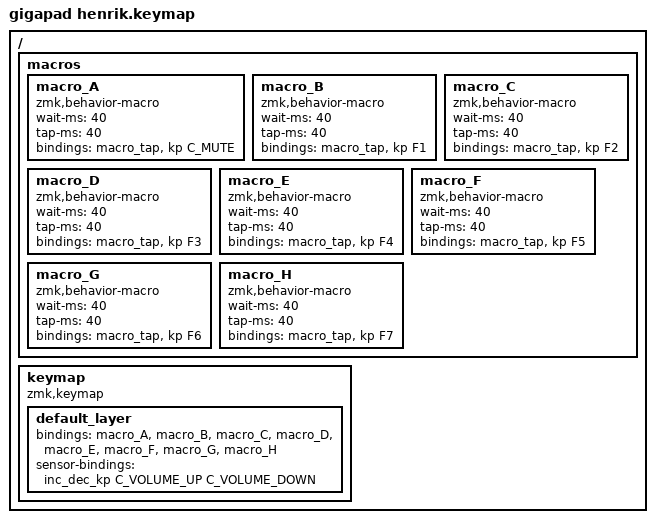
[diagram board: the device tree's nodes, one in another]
#include <behaviors.dtsi>
#include <dt-bindings/zmk/keys.h>
#include <dt-bindings/zmk/bt.h>
#include <dt-bindings/zmk/outputs.h>

/ {
    macros {
        macro_A: macro_A {
            compatible = "zmk,behavior-macro";
            #binding-cells = <0>;
            wait-ms = <40>;
            tap-ms = <40>;
            bindings = 
                <&macro_tap &kp C_MUTE>;
        };
        macro_B: macro_B {
            compatible = "zmk,behavior-macro";
            #binding-cells = <0>;
            wait-ms = <40>;
            tap-ms = <40>;
            bindings = 
                <&macro_tap &kp F1>;
        };
        macro_C: macro_C {
            compatible = "zmk,behavior-macro";
            #binding-cells = <0>;
            wait-ms = <40>;
            tap-ms = <40>;
            bindings = 
                <&macro_tap &kp F2>;
        };
        macro_D: macro_D {
            compatible = "zmk,behavior-macro";
            #binding-cells = <0>;
            wait-ms = <40>;
            tap-ms = <40>;
            bindings = 
                <&macro_tap &kp F3>;
        };
        macro_E: macro_E {
            compatible = "zmk,behavior-macro";
            #binding-cells = <0>;
            wait-ms = <40>;
            tap-ms = <40>;
            bindings = 
                <&macro_tap &kp F4>;
        };
        macro_F: macro_F {
            compatible = "zmk,behavior-macro";
            #binding-cells = <0>;
            wait-ms = <40>;
            tap-ms = <40>;
            bindings = 
                <&macro_tap &kp F5>;
        };
        macro_G: macro_G {
            compatible = "zmk,behavior-macro";
            #binding-cells = <0>;
            wait-ms = <40>;
            tap-ms = <40>;
            bindings = 
                <&macro_tap &kp F6>;
        };
        macro_H: macro_H {
            compatible = "zmk,behavior-macro";
            #binding-cells = <0>;
            wait-ms = <40>;
            tap-ms = <40>;
            bindings = 
                <&macro_tap &kp F7>;
        };
    };
    keymap {
        compatible = "zmk,keymap";

        default_layer {
            bindings = <
                &macro_A  &macro_B  &macro_C  &macro_D  &macro_E  &macro_F  &macro_G  &macro_H
            >;
            sensor-bindings = <&inc_dec_kp C_VOLUME_UP C_VOLUME_DOWN>;
        };
    };
};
